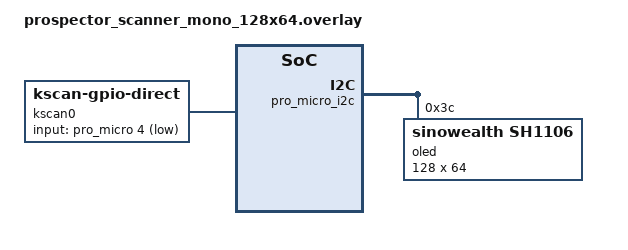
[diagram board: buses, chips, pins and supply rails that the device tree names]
/*
 * Prospector Scanner (mono OLED variant)
 * nice!nano v2 + 1.3" SH1106 128x64 I2C OLED
 */

#include <dt-bindings/zmk/matrix_transform.h>

/ {
    chosen {
        zmk,kscan = &kscan0;
        zmk,display = &oled;
        zephyr,display = &oled;
    };

    /*
     * ZMK requires a kscan device. This is a display-only scanner with no
     * keys, so provide a 1x1 dummy direct kscan on an unused pro-micro pin.
     */
    kscan0: kscan {
        compatible = "zmk,kscan-gpio-direct";
        wakeup-source;
        input-gpios = <&pro_micro 4 (GPIO_ACTIVE_LOW | GPIO_PULL_UP)>;
    };
};

/*
 * pro_micro_i2c maps to nice!nano I2C (SDA=P0.17, SCL=P0.20). The board
 * already provides pinctrl; we just enable the bus and attach the panel.
 */
&pro_micro_i2c {
    status = "okay";

    oled: sh1106@3c {
        compatible = "sinowealth,sh1106";
        reg = <0x3c>;
        width = <128>;
        height = <64>;
        /* SH1106 RAM is 132 columns wide; a 128px panel is centered -> +2 */
        segment-offset = <2>;
        page-offset = <0>;
        display-offset = <0>;
        multiplex-ratio = <63>;
        segment-remap;
        com-invdir;
        prechargep = <0x22>;
    };
};
